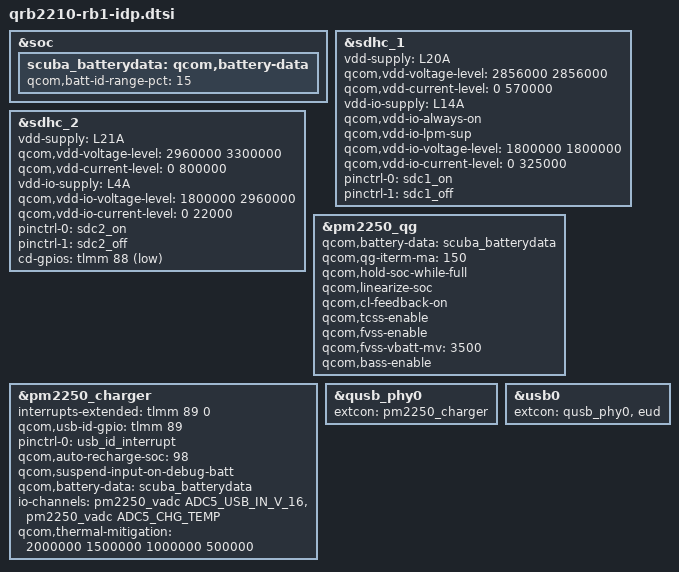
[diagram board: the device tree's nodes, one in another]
#include <dt-bindings/clock/qcom,gcc-scuba.h>
#include <dt-bindings/clock/qcom,gpucc-scuba.h>
#include <dt-bindings/gpio/gpio.h>
#include <dt-bindings/iio/qcom,spmi-vadc.h>
#include "qrb2210-rb1-ion.dtsi"

&soc {
	scuba_batterydata: qcom,battery-data {
		qcom,batt-id-range-pct = <15>;
		#include "qg-batterydata-alium-3600mah.dtsi"
		#include "qg-batterydata-atl466271_3300mAh.dtsi"
	};
};

&sdhc_1 {
	vdd-supply = <&L20A>;
	qcom,vdd-voltage-level = <2856000 2856000>;
	qcom,vdd-current-level = <0 570000>;

	vdd-io-supply = <&L14A>;
	qcom,vdd-io-always-on;
	qcom,vdd-io-lpm-sup;
	qcom,vdd-io-voltage-level = <1800000 1800000>;
	qcom,vdd-io-current-level = <0 325000>;

	pinctrl-names = "default", "sleep";
	pinctrl-0 = <&sdc1_on>;
	pinctrl-1 = <&sdc1_off>;

	status = "ok";
};

&sdhc_2 {
	vdd-supply = <&L21A>;
	qcom,vdd-voltage-level = <2960000 3300000>;
	qcom,vdd-current-level = <0 800000>;

	vdd-io-supply = <&L4A>;
	qcom,vdd-io-voltage-level = <1800000 2960000>;
	qcom,vdd-io-current-level = <0 22000>;

	pinctrl-names = "default", "sleep";
	pinctrl-0 = <&sdc2_on>;
	pinctrl-1 = <&sdc2_off>;

	cd-gpios = <&tlmm 88 GPIO_ACTIVE_LOW>;

	status = "ok";
};

&pm2250_qg {
	qcom,battery-data = <&scuba_batterydata>;
	qcom,qg-iterm-ma = <150>;
	qcom,hold-soc-while-full;
	qcom,linearize-soc;
	qcom,cl-feedback-on;
	qcom,tcss-enable;
	qcom,fvss-enable;
	qcom,fvss-vbatt-mv = <3500>;
	qcom,bass-enable;
};

&pm2250_charger {
	interrupts-extended = <&tlmm 89 0>;
	interrupt-names = "usb_id_irq";
	qcom,usb-id-gpio = <&tlmm 89 0>;

	pinctrl-names = "default";
	pinctrl-0 = <&usb_id_interrupt>;

	qcom,auto-recharge-soc = <98>;
	qcom,suspend-input-on-debug-batt;
	qcom,battery-data = <&scuba_batterydata>;
	io-channels = <&pm2250_vadc ADC5_USB_IN_V_16>,
			<&pm2250_vadc ADC5_CHG_TEMP>;
	io-channel-names = "usb_in_voltage",
			"chg_temp";
	qcom,thermal-mitigation = <2000000 1500000 1000000 500000>;
};

&qusb_phy0 {
	extcon = <&pm2250_charger>;
};

&usb0 {
	extcon = <&qusb_phy0>, <&eud>;
};
